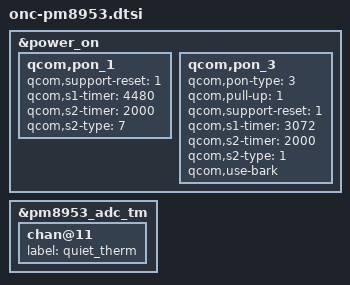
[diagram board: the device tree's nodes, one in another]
/*
 * Copyright (c) 2015-2019, The Linux Foundation. All rights reserved.
 * Copyright (C) 2020-2024 XiaoMi, Inc.
 *
 * This program is free software; you can redistribute it and/or modify
 * it under the terms of the GNU General Public License version 2 and
 * only version 2 as published by the Free Software Foundation.
 */

&power_on {
	qcom,pon_1 {
		qcom,support-reset = <1>;
		qcom,s1-timer = <4480>;
		qcom,s2-timer = <2000>;
		qcom,s2-type = <7>;
	};
	qcom,pon_3 {
		qcom,pon-type = <3>;
		qcom,pull-up = <1>;
		qcom,support-reset = <1>;
		qcom,s1-timer = <3072>;
		qcom,s2-timer = <2000>;
		qcom,s2-type = <1>;
		qcom,use-bark;
	};
};

&pm8953_adc_tm {
	chan@11 {
		label = "quiet_therm";
	};
};
